# IND83215A register map
Series: Verne; File version: A0
CPU: CM0 r0p1, selectable endian, no MPU, no FPU, 4 interrupt priority bits
Registers are 32-bit, read-write, no defined reset value unless marked. A register's access mark holds for its fields unless they carry their own. Offsets are from the block's base; [hi:lo] are bit positions; {n}, {i} and the like mark numbered series.

## PWM — Control (and status) registers for the pulse width modulation waveform generator.
Base 0x50010000; register names take the prefix PWM_
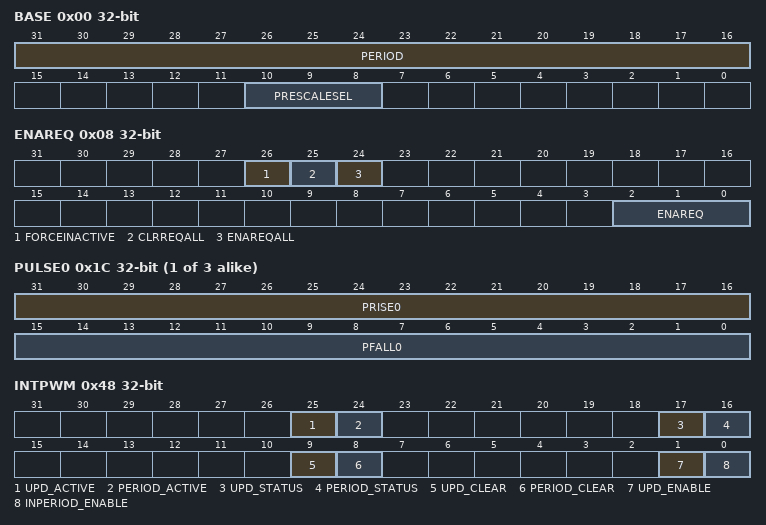
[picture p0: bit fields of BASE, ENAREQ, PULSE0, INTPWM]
0x00 BASE — Base Function
  [31:16] PERIOD — Period. Specifies the period of the output waveform in terms of a number of prescaler output cycles.
  [10:8] PRESCALESEL — Prescaler select. Defines the ratio between the system clock and the clock used for the waveform generator. 0x0: Divide by 1 0x1: Divide by 2 0x2: Divide by 4 0x3: Divide by 8 0x4: Divide by 16 0x5: Divide by 64 0x6: Divide by 256 0x7: Divide by 1024
0x04 PWMCNT — PWM Count Value.
  [15:0] PWMCNT dual — PWM counter value to give a sense about the current period
0x08 ENAREQ — Enable request.
  [26] FORCEINACTIVE — Set to force PWM signals return to initial value immediately.
  [25] CLRREQALL wo — Write 1 to clear all ENA_REQ bits; Write 0 has no effects.
  [24] ENAREQALL wo — Write 1 to enable all ENA_REQ bits; Write 0 has no effects.
  [2:0] ENAREQ — Set to enable the waveform generator.
0x0C ENASTS — Enable status.
  [2:0] ENASTS ro — Status of enable in the waveform generator.
0x10 INIT — Intial State of Outputs.
  [2:0] INIT — Set to initialise the output waveform.
0x14 INV — Invert.
  [2:0] INVERT — Set to invert the output waveform.
0x18 UPDATE
  [0] UPDATE dual — Set to trigger consumption of new PULSE parameters (invert,prescale_sel,period,pulse start & stop). The flag is automatically cleared by the hardware when the settings are consumed, so reading a high value indicates that an update is still pending.
{0x1C+4i} PULSE{i} (i=0..2) — PWM{i} pulse setup.
  [31:16] PRISE{i} — Pulse Rise. Specifies the pulse rise of the output waveform in terms of a number of prescaler output cycles. However, if INVERT is set it determines the pulse fall timing.
  [15:0] PFALL{i} — Pulse Fall. Specifies the pulse fall of the output waveform in terms of a number of prescaler output cycles. However, if INVERT is set it determines the pulse rise timing.
0x28 INTPOSEDGENA — PWM posedge interrupt enable. Contains the enable for the PWM posedge interrupt sources.
  [2:0] INTPOSEDGENA — Interrupt enable. bit[2:0]: posedge interrupt enable.
0x2C INTNEGEDGENA — PWM negedge interrupt enable. Contains the enable for the PWM negedge interrupt sources.
  [2:0] INTNEGEDGENA — Interrupt enable. bit[2:0]: negedge interrupt enable.
0x30 INTPOSEDGCLR — PWM posedge interrupt control. Contains the clear for the PWM posedge interrupt sources.
  [2:0] INTPOSEDGCLR wo — Interrupt clear. bit[2:0] : posedge interrupt clear.
0x34 INTNEGEDGCLR — PWM negedge interrupt control. Contains the clear for the PWM negedge interrupt sources.
  [2:0] INTNEGEDGCLR wo — Interrupt clear. bit[2:0] : negedge interrupt clear.
0x38 INTPOSEDGSTS — PWM posedge interrupt status. Contains the status for the PWM posedge interrupt sources.
  [2:0] INTPOSEDGSTS ro — Interrupt status. bit[2:0] : posedge interrupt status.
0x3C INTNEGEDGSTS — PWM negedge interrupt status. Contains the status for the PWM negedge interrupt sources.
  [2:0] INTNEGEDGSTS ro — Interrupt status. bit[2:0] : negedge interrupt status.
0x40 INTPOSEDGIRQ — PWM posedge interrupt active. Contains the active for the PWM posedge interrupt sources.
  [2:0] INTPOSEDGIRQ ro — Interrupt active. bit[2:0] : posedge interrupt active.
0x44 INTNEGEDGIRQ — PWM negedge interrupt active. Contains the active for the PWM negedge interrupt sources.
  [2:0] INTNEGEDGIRQ ro — Interrupt active. bit[2:0] : negedge interrupt active.
0x48 INTPWM — PWM interrupt control. Contains the enable, clear, status and active for the PWM period & updated interrupt sources.
  [25] UPD_ACTIVE ro — Updated Interrupt active.
  [24] PERIOD_ACTIVE ro — Period Interrupt active.
  [17] UPD_STATUS ro — Updated Interrupt status.
  [16] PERIOD_STATUS ro — Period Interrupt status.
  [9] UPD_CLEAR wo — Updated Interrupt clear.
  [8] PERIOD_CLEAR wo — Period Interrupt clear.
  [1] UPD_ENABLE — Updated Interrupt enable.
  [0] INPERIOD_ENABLE — Period Interrupt enable.
